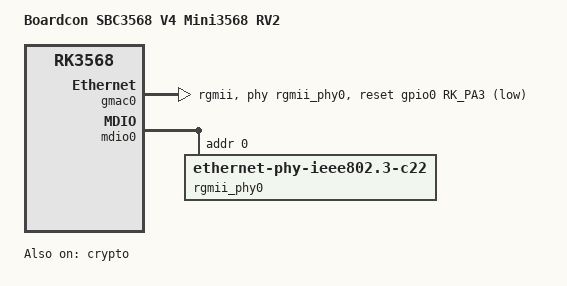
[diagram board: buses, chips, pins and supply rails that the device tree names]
// SPDX-License-Identifier: (GPL-2.0+ OR MIT)
/*
 * Copyright (c) 2021 Rockchip Electronics Co., Ltd
 *
 */

/dts-v1/;
#include "rk3568.dtsi"
#include "rk3568-u-boot.dtsi"
#include <dt-bindings/input/input.h>


/ {
	model = "Boardcon SBC3568 V4 Mini3568 RV2";
	compatible = "boardcon,sbc3568", "rockchip,rk3568";
};


&gmac0 {
	phy-mode = "rgmii";
	clock_in_out = "output";

	snps,reset-gpio = <&gpio0 RK_PA3 GPIO_ACTIVE_LOW>;
	snps,reset-active-low;
	/* Reset time is 20ms, 100ms for rtl8211f */
	snps,reset-delays-us = <0 20000 100000>;
	assigned-clocks = <&cru SCLK_GMAC0_RX_TX>, <&cru SCLK_GMAC0>;
	assigned-clock-parents = <&cru SCLK_GMAC0_RGMII_SPEED>;
	assigned-clock-rates = <0>, <125000000>;

	pinctrl-names = "default";
	pinctrl-0 = <&gmac0_miim
		     &gmac0_tx_bus2
		     &gmac0_rx_bus2
		     &gmac0_rgmii_clk
		     &gmac0_rgmii_bus>;

	tx_delay = <0x3c>;
	rx_delay = <0x2f>;

	phy-handle = <&rgmii_phy0>;
	status = "okay";
};

&mdio0 {
	rgmii_phy0: phy@0 {
		compatible = "ethernet-phy-ieee802.3-c22";
		reg = <0x0>;
	};
};

&crypto {
	status = "okay";
};

&usbdrd30 {
	status = "disabled";
};

&usbdrd_dwc3 {
	status = "disabled";
};


